# M2354 register map
File version: 1.0
Registers are 32-bit, read-write, reset 0x0 unless marked. A register's access mark holds for its fields unless they carry their own. Offsets are from the block's base; [hi:lo] are bit positions.

## EWDT_NS — EWDT Register Map
Base 0x50042000
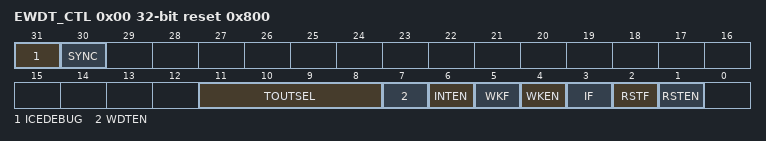
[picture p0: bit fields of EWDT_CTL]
0x00 EWDT_CTL reset 0x800 — Extra WDT Control Register
  [31] ICEDEBUG — ICE Debug Mode Acknowledge Disable Bit (Write Protect). EWDT up counter will keep going no matter CPU is held by ICE or not. Note: This bit is write protected. Refer to the SYS_REGLCTL register.
    0=ICE debug mode acknowledgement affects EWDT counting; 1=ICE debug mode acknowledgement Disabled
  [30] SYNC ro — EWDT Enable Control SYNC Flag Indicator (Read Only). If user executes enable/disable WDTEN (EWDT_CTL[7]), this flag can indicate enable/disable WDTEN function is completed or not. Note: Performing enable or disable WDTEN bit needs 2 * EWDT_CLK period to become active.
    0=Set WDTEN bit is completed; 1=Set WDTEN bit is synchronizing and not become active yet
  [11:8] TOUTSEL — WDT Time-out Interval Selection (Write Protect). These three bits select the time-out interval period for the WDT. Note: This bit is write protected. Refer to the SYS_REGLCTL register.
    0=24 * EWDT_CLK; 1=26 * EWDT_CLK; 2=28 * EWDT_CLK; 3=210 * EWDT_CLK; 4=212 * EWDT_CLK; 5=214 * EWDT_CLK; 6=216 * EWDT_CLK; 7=218 * EWDT_CLK; 8=220 * EWDT_CLK
  [7] WDTEN — WDT Enable Bit (Write Protect). Note: This bit is write protected. Refer to the SYS_REGLCTL register.
    0=EWDT Disabled (this action will reset the internal up counter value); 1=EWDT Enabled
  [6] INTEN — EWDT Time-out Interrupt Enable Bit (Write Protect). If this bit is enabled, the EWDT time-out interrupt signal is generated and inform to CPU. Note: This bit is write protected. Refer to the SYS_REGLCTL register.
    0=EWDT time-out interrupt Disabled; 1=EWDT time-out interrupt Enabled
  [5] WKF — WDT Time-out Wake-up Flag. This bit indicates the interrupt wake-up flag status of EWDT. Note: This bit is cleared by writing 1 to it.
    0=EWDT does not cause chip wake-up; 1=Chip wake-up from Idle or Power-down mode if EWDT time-out interrupt signal generated
  [4] WKEN — WDT Time-out Wake-up Function Control (Write Protect). If this bit is set to 1, while EWDT time-out interrupt flag IF (EWDT_CTL[3]) is generated to 1 and interrupt enable bit INTEN (EWDT_CTL[6]) is enabled, the EWDT time-out interrupt signal will generate a wake-up trigger event to chip. Note 1: This bit is write protected. Refer to the SYS_REGLCTL register. Note 2: Chip can be woken up by EWDT time-out interrupt signal generated only if EWDT clock source is selected to 32 kHz internal low speed RC oscillator (LIRC) or LXT.
    0=Wake-up trigger event Disabled if EWDT time-out interrupt signal generated; 1=Wake-up trigger event Enabled if EWDT time-out interrupt signal generated
  [3] IF — EWDT Time-out Interrupt Flag. This bit will set to 1 while EWDT up counter value reaches the selected EWDT time-out interval. Note: This bit is cleared by writing 1 to it.
    0=EWDT time-out interrupt did not occur; 1=EWDT time-out interrupt occurred
  [2] RSTF — EWDT Time-out Reset Flag. This bit indicates the system has been reset by EWDT time-out reset or not. Note: This bit is cleared by writing 1 to it.
    0=EWDT time-out reset did not occur; 1=EWDT time-out reset occurred
  [1] RSTEN — EWDT Time-out Reset Enable Bit (Write Protect). Setting this bit will enable the EWDT time-out reset function if the EWDT up counter value has not been cleared after the specific EWDT reset delay period expires. Note: This bit is write protected. Refer to the SYS_REGLCTL register.
    0=EWDT time-out reset function Disabled; 1=EWDT time-out reset function Enabled
0x04 EWDT_ALTCTL — Extra WDT Alternative Control Register
  [1:0] RSTDSEL — WDT Reset Delay Selection (Write Protect). When EWDT time-out happened, user has a time named EWDT Reset Delay Period to clear EWDT counter by programming 0x5AA5 to RSTCNT to prevent EWDT time-out reset happened. User can select a suitable setting of RSTDSEL for different EWDT Reset Delay Period. Note 1: This bit is write protected. Refer to the SYS_REGLCTL register. Note 2: This register will be reset to 0 if EWDT time-out reset happened.
    0=EWDT Reset Delay Period is 1026 * EWDT_CLK; 1=EWDT Reset Delay Period is 130 * EWDT_CLK; 2=EWDT Reset Delay Period is 18 * EWDT_CLK; 3=EWDT Reset Delay Period is 3 * EWDT_CLK
0x08 EWDT_RSTCNT wo — Extra WDT Reset Counter Register
  [31:0] RSTCNT — WDT Reset Counter Register. Writing 0x00005AA5 to this field will reset the internal 20-bit EWDT up counter value to 0. Note: Performing RSTCNT to reset counter needs 2 * EWDT_CLK period to become active.
